# YTM32B1MD2 register map
Vendor: YTMicro; File version: 1.0
YTM32B1MD2 YTMicro Microcontroller
CPU: CM33 r0p4, little endian, MPU, FPU, 2 interrupt priority bits
Registers are 32-bit, read-write, reset 0x0 unless marked. A register's access mark holds for its fields unless they carry their own. Offsets are from the block's base; lines under a group give offsets from that group; [hi:lo] are bit positions; {n}, {i} and the like mark numbered series; 'fields as' and 'values as' point back to an identical list; <NAME> marks a mode.

## Memory map
0x40008000 DMA0 size 0x1200 — Direct Memory Access
0x40010000 EFM size 0x30C — Embedded Flash Module
0x40011000 GPIOA size 0xFF — General Purpose Input/Output
0x40011100 GPIOB size 0xFF — General Purpose Input/Output
0x40011200 GPIOC size 0xFF — General Purpose Input/Output
0x40011300 GPIOD size 0xFF — General Purpose Input/Output
0x40011400 GPIOE size 0xFF — General Purpose Input/Output
0x40012000 PCTRLA size 0x80 — PORT Control
0x40013000 PCTRLB size 0x80 — PORT Control
0x40014000 PCTRLC size 0x80 — PORT Control
0x40015000 PCTRLD size 0x80 — PORT Control
0x40016000 PCTRLE size 0x80 — PORT Control
0x4001B000 UART0 size 0x20 — UART module with LIN mode support
0x4001C000 UART1 size 0x20 — UART module with LIN mode support
0x4001D000 UART2 size 0x20 — UART module with LIN mode support
0x40023000 I2C0 size 0x120 — Inter-Integrated Circuit
0x40024000 I2C1 size 0x120 — Inter-Integrated Circuit
0x4002A000 SPI0 size 0x28 — Serial Port Interface
0x4002B000 SPI1 size 0x28 — Serial Port Interface
0x4002C000 SPI2 size 0x28 — Serial Port Interface
0x40030000 CAN0 size 0xC08 — FlexCAN module
0x40034000 CAN1 size 0xC08 — FlexCAN module
0x40038000 CAN2 size 0xC08 — FlexCAN module
0x40040000 eADC0 size 0x110 — Enhanced Analog-to-Digital Converter
0x40043000 ACMP0 size 0x34 — Analog comparator module
0x40048000 TMU size 0x10 — Trigger Multiplexer Module
0x40049000 eTMR0 size 0x268 — Enhanced timer
0x4004A000 eTMR1 size 0x268 — Enhanced timer
0x4004F000 MPWM0 size 0x400 — Multiple Pulse Width Modulation
0x4005A000 pTMR0 size 0x140 — Periodic timer
0x4005D000 lpTMR0 size 0x18 — Low Power Timer
0x40060000 RTC size 0x20 — Real Time Clock provides a real time counter which is present in always on domain.
0x40065000 CRC0 size 0x10 — Cyclic Redundancy Check
0x40066000 TRNG0 size 0x50 — True Random Number Generator
0x40067000 HCU size 0x720 — Hardware Cryptography Unit
0x4006A000 WDG0 size 0x20 — Watchdog module
0x4006B000 EWDG0 size 0x14 — External Watchdog
0x40072000 EMU0 size 0x16C — ECC Management Unit
0x40076000 CMU0 size 0x48 — Clock monitor unit
0x40077000 CFMU0 size 0x1C — Clock frequency measure unit
0x4007B000 CIM size 0x48 — Chip Integration Module of Microcontroller
0x4007C000 SCU size 0x58 — System Clock Unit of Microcontroller
0x4007D000 IPC size 0x1FC — IP Control
0x4007E000 PCU size 0x14 — Power control unit
0x4007F000 RCU size 0x8 — Reset Control Unit of Micro-controller
0xE0080000 CACHE size 0x64 — Cache Controller and Cache Array

## GPIOA — General Purpose Input/Output
Base 0x40011000; register names take the prefix GPIOA_
0x00 PDOR
  [31:0] PDO — When configured for general-purpose output, it shows the logic level on the corresponding pin.
0x04 PSOR wo
  [31:0] PSO — Writing to this register will update the contents of the corresponding bit in PDOR.
    0=0b (No change.); 1=1b (Corresponding bit in PDOR is set to logic 1.)
0x08 PCOR wo
  [31:0] PCO — Writing to this register will update the contents of the corresponding bit in PDOR.
    0=0b (No change.); 1=1b (Corresponding bit in PDOR is set to logic 0.)
0x0C PTOR wo
  [31:0] PTO — Writing to this register will update the contents of the corresponding bit in PDOR.
    0=0b (No change.); 1=1b (Corresponding bit in PDOR is set to the inverse of its existing logic state.)
0x10 PDIR ro
  [31:0] PDI — When configured for digital function, it shows the logic level on the corresponding pin. ewline When configured for analog function, it always reads 0.
0x14 POER
  [31:0] POE — Configure the corresponding pin for output.
    0=0b (Port output disable); 1=1b (Port output enable)
0x18 PIER reset 0xFFFFFFFF
  [31:0] PIE — Configure the corresponding pin for input.
    0=0b (Port input disable); 1=1b (Port input enable)
0x1C PIFR
  [31:0] PIF — Indicate the detection for the defined event in PCTRL[IRQC] of the corresponding pin.
    0=0b (No event detected.); 1=1b (The event defined in PCTRL[IRQC] is detected.)
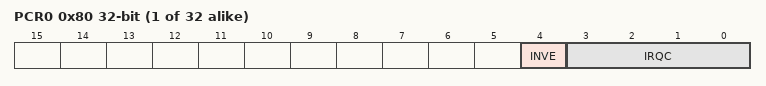
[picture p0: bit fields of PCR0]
{0x80+4i} PCR{i} (i=0..31)
  [4] INVE — Invert the input logic level when configured for digital function.
  [3:0] IRQC
    0=Disabled; 8=Interrupt when logic 0; 9=Interrupt on rising-edge; 10=Interrupt on falling-edge; 11=Interrupt on either edge; 12=Interrupt when logic 1

## GPIOB — General Purpose Input/Output
Base 0x40011100; register names take the prefix GPIOB_
Registers as GPIOA.

## GPIOC — General Purpose Input/Output
Base 0x40011200; register names take the prefix GPIOC_
Registers as GPIOA.

## GPIOD — General Purpose Input/Output
Base 0x40011300; register names take the prefix GPIOD_
Registers as GPIOA.

## GPIOE — General Purpose Input/Output
Base 0x40011400; register names take the prefix GPIOE_
Registers as GPIOA.

## Licence text in the file
YTMicro Microcontroller all rights reserved.
